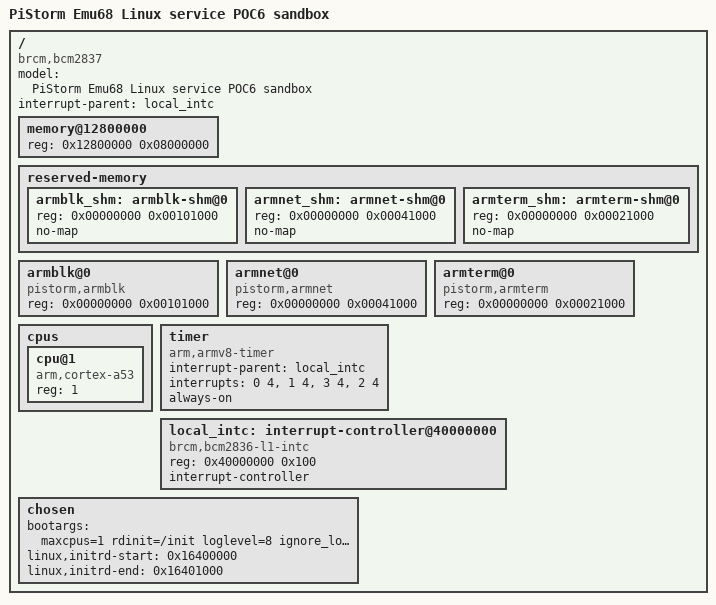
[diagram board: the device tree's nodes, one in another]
/dts-v1/;

/ {
    model = "PiStorm Emu68 Linux service POC6 sandbox";
    compatible = "brcm,bcm2837", "brcm,bcm2836";

    #address-cells = <1>;
    #size-cells = <1>;
    interrupt-parent = <&local_intc>;

    /* POC5 rewrites this to the actual ARM-service carveout. */
    memory@12800000 {
        device_type = "memory";
        reg = <0x12800000 0x08000000>;
    };


    /*
     * armblk, armnet and armterm live inside the dynamically assigned 128 MiB
     * ARM-service RAM. Linux.c patches their reg addresses to:
     *     armblk: armservice_phys_base + 0x039e0000
     *     armnet:  armservice_phys_base + 0x03b00000
     *     armterm: armservice_phys_base + 0x03b80000
     *
     * Both regions are deliberately below:
     *     initramfs +0x03c00000
     *     DTB       +0x03e00000
     *
     * reserved-memory keeps the Linux page allocator out of the ring area.
     */
    reserved-memory {
        #address-cells = <1>;
        #size-cells = <1>;
        ranges;

        armblk_shm: armblk-shm@0 {
            reg = <0x00000000 0x00101000>;
            no-map;
        };

        armnet_shm: armnet-shm@0 {
            reg = <0x00000000 0x00041000>;
            no-map;
        };

        armterm_shm: armterm-shm@0 {
            reg = <0x00000000 0x00021000>;
            no-map;
        };
    };

    armblk@0 {
        compatible = "pistorm,armblk";
        reg = <0x00000000 0x00101000>;
        status = "okay";
    };

    armnet@0 {
        compatible = "pistorm,armnet";
        reg = <0x00000000 0x00041000>;
        status = "okay";
    };

    armterm@0 {
        compatible = "pistorm,armterm";
        reg = <0x00000000 0x00021000>;
        status = "okay";
    };

    /* Linux is entered on physical Cortex-A53 core 1.  Expose only that CPU. */
    cpus {
        #address-cells = <1>;
        #size-cells = <0>;

        cpu@1 {
            device_type = "cpu";
            compatible = "arm,cortex-a53", "arm,armv8";
            reg = <1>;
        };
    };

    /* ARM generic timer only.  No firmware clock provider is needed. */
    timer {
        compatible = "arm,armv8-timer", "arm,armv7-timer";
        interrupt-parent = <&local_intc>;
        interrupts = <0 4>, <1 4>, <3 4>, <2 4>;
        always-on;
    };

    /* BCM2836/7 per-core local interrupt controller.  This is the only
       hardware block intentionally exposed to Linux in POC6. */
    local_intc: interrupt-controller@40000000 {
        compatible = "brcm,bcm2836-l1-intc";
        reg = <0x40000000 0x100>;
        interrupt-controller;
        #interrupt-cells = <2>;
        phandle = <1>;
        linux,phandle = <1>;
    };

    chosen {
        bootargs = "maxcpus=1 rdinit=/init loglevel=8 ignore_loglevel";
        linux,initrd-start = <0x16400000>;
        linux,initrd-end = <0x16401000>;
    };
};
